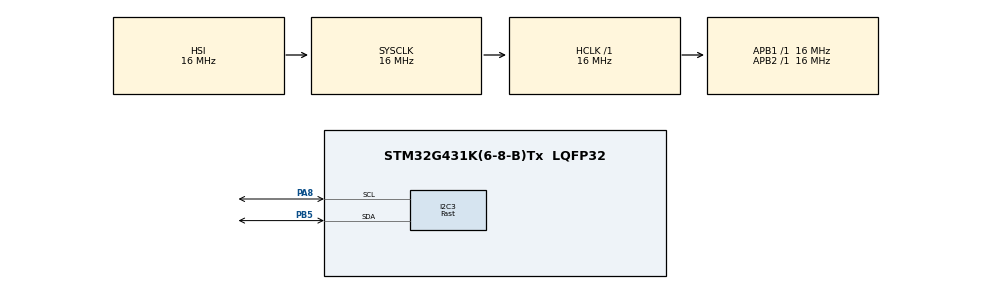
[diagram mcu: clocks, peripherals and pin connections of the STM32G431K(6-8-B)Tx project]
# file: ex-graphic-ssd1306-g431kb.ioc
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I2C3.I2C_Speed_Mode=I2C_Fast
I2C3.Timing=0x00300617
Mcu.Family=STM32G4
Mcu.Name=STM32G431K(6-8-B)Tx
Mcu.Package=LQFP32
NVIC.PriorityGroup=NVIC_PRIORITYGROUP_4
PA13.Mode=Serial_Wire
PA13.Signal=SYS_JTMS-SWDIO
PA14.Mode=Serial_Wire
PA14.Signal=SYS_JTCK-SWCLK
PA8.Mode=I2C
PA8.Signal=I2C3_SCL
PB5.Mode=I2C
PB5.Signal=I2C3_SDA
ProjectManager.HeapSize=0x200
ProjectManager.StackSize=0x400
ProjectManager.TargetToolchain=STM32CubeIDE
RCC.AHBFreq_Value=16000000
RCC.APB1Freq_Value=16000000
RCC.APB1TimFreq_Value=16000000
RCC.APB2Freq_Value=16000000
RCC.APB2TimFreq_Value=16000000
RCC.CortexFreq_Value=16000000
RCC.EXTERNAL_CLOCK_VALUE=12288000
RCC.HCLKFreq_Value=16000000
RCC.HSE_VALUE=8000000
RCC.HSI48_VALUE=48000000
RCC.HSI_VALUE=16000000
RCC.LSE_VALUE=32768
RCC.SYSCLKFreq_VALUE=16000000
RCC.USBFreq_Value=64000000
RCC.VCOOutputFreq_Value=128000000
VP_SYS_VS_DBSignals.Mode=DisableDeadBatterySignals
board=custom

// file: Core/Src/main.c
/* USER CODE BEGIN Header */
/**
  ******************************************************************************
  * @file           : main.c
  * @brief          : Main program body
  ******************************************************************************
  * @attention
  *
  * Copyright (c) 2024 STMicroelectronics.
  * All rights reserved.
  *
  * This software is licensed under terms that can be found in the LICENSE file
  * in the root directory of this software component.
  * If no LICENSE file comes with this software, it is provided AS-IS.
  *
  ******************************************************************************
  */
/* USER CODE END Header */
#include "main.h"

/* USER CODE BEGIN Includes */
#include "drivers/ssd1306/ssd1306.h"

#include "GraphicDisplay.h"
#include "GraphicDisplay_Fonts.h"
/* USER CODE END Includes */

I2C_HandleTypeDef hi2c3;

/* USER CODE BEGIN PV */
#define cobra_width 	 64
#define cobra_height 	 64
const unsigned char cobra_bmp [] ={
0x00,0x00,0x00,0xb4,0x00,0x00,0x00,0x00,0x00,0x00,0x00,0xef,0x03,0x00,0x00,0x00,
0x00,0x00,0xc0,0x00,0x06,0x00,0x00,0x00,0x00,0x00,0x60,0x00,0x18,0x00,0x00,0x00,
0x00,0x00,0x30,0x0e,0x30,0x00,0x00,0x00,0x00,0x00,0x98,0x1b,0x70,0x00,0x00,0x00,
0x00,0x00,0x88,0x30,0xd0,0x00,0x00,0x00,0x00,0x00,0x84,0x68,0x90,0x01,0x00,0x00,
0x00,0x00,0xc6,0xdc,0x30,0x03,0x00,0x00,0x00,0x00,0x82,0x87,0x21,0x06,0x00,0x00,
0x00,0x00,0x02,0x03,0xc3,0x0c,0x00,0x00,0x00,0x00,0x03,0x01,0x86,0x3f,0x00,0x00,
0x00,0x00,0x81,0x01,0x0c,0xe0,0x00,0x00,0x00,0x00,0x81,0x00,0x18,0x80,0x03,0x00,
0x00,0x00,0x83,0x00,0x70,0x00,0x06,0x00,0x00,0x00,0x8f,0x00,0x40,0x00,0x04,0x00,
0x00,0x00,0x99,0x00,0xc0,0x01,0x0c,0x00,0x00,0x00,0x91,0x00,0x00,0x03,0x04,0x00,
0x00,0x00,0xb1,0x01,0x00,0x06,0x04,0x00,0x00,0x00,0x93,0x00,0x00,0x0c,0x0c,0x00,
0x00,0x00,0x11,0x01,0x00,0x08,0x04,0x00,0x00,0x00,0x1a,0x03,0x00,0x18,0x08,0x00,
0x00,0x00,0x0e,0x06,0x00,0x10,0x08,0x00,0x00,0x00,0x06,0x06,0x00,0x30,0x08,0x00,
0x00,0x00,0x04,0x1b,0x00,0x60,0x0c,0x00,0x00,0x00,0x0c,0x32,0x00,0xc0,0x07,0x00,
0x00,0x00,0x18,0x63,0x00,0x80,0x04,0x00,0x00,0x00,0x30,0xc6,0x00,0x00,0x0c,0x00,
0x00,0x00,0x60,0xcc,0x01,0x00,0x08,0x00,0x00,0x00,0xc0,0x78,0x03,0x00,0x38,0x00,
0x00,0x00,0x80,0x01,0x06,0x00,0x68,0x00,0x00,0x00,0x00,0x03,0x1c,0x00,0x0c,0x00,
0x00,0x00,0x20,0x06,0x18,0x00,0x00,0x00,0x00,0x00,0xfe,0xff,0xff,0x7f,0x00,0x00,
0x00,0x00,0x03,0x20,0x08,0xc0,0x00,0x00,0x00,0x00,0x01,0x60,0x0c,0x80,0x00,0x00,
0x00,0x80,0x01,0xc0,0x07,0x80,0x01,0x00,0x00,0x80,0x00,0x80,0x02,0x00,0x01,0x00,
0x00,0x00,0x01,0x00,0x00,0x80,0x00,0x00,0x00,0x00,0x03,0x00,0x00,0xc0,0x00,0x00,
0x00,0xe0,0xff,0xff,0xff,0xff,0x07,0x00,0x00,0x38,0x49,0xb2,0x2c,0x49,0x1a,0x00,
0x00,0x08,0x00,0x60,0x08,0x00,0x10,0x00,0x00,0x0c,0x00,0x40,0x0e,0x00,0x30,0x00,
0x00,0x04,0xf0,0xc0,0x03,0x1e,0x20,0x00,0x00,0x08,0x98,0x01,0x00,0x33,0x30,0x00,
0x00,0x08,0x0c,0x01,0x00,0x61,0x10,0x00,0x00,0xba,0x4c,0x2b,0xd5,0x65,0x5e,0x00,
0x80,0xff,0xff,0xff,0xff,0xff,0xff,0x01,0xc0,0x00,0x00,0x20,0x08,0x00,0x00,0x03,
0x40,0x00,0x00,0x60,0x0c,0x00,0x00,0x02,0x60,0x00,0x14,0xc0,0x07,0x50,0x00,0x06,
0x20,0x00,0x3e,0x00,0x01,0xf8,0x00,0x04,0x40,0x00,0x63,0x00,0x00,0x8c,0x01,0x02,
0xc0,0x00,0x41,0x00,0x00,0x04,0x01,0x03,0xf8,0xff,0xff,0xff,0xff,0xff,0xff,0x1f,
0x0e,0x82,0x20,0x28,0x89,0x20,0x08,0x72,0x02,0x00,0x00,0x60,0x0c,0x00,0x00,0x40,
0x03,0x40,0x00,0x40,0x06,0x00,0x02,0xc0,0x02,0xf0,0x01,0xc0,0x03,0x80,0x0f,0x80,
0x03,0x18,0x03,0x00,0x00,0xc0,0x18,0x40,0x02,0x08,0x02,0x00,0x00,0x40,0x10,0x60,
0xae,0x5a,0x57,0x55,0xb5,0xea,0x5e,0x35,0xf8,0xff,0xff,0xff,0xff,0xff,0xff,0x1f};
/* USER CODE END PV */

void SystemClock_Config(void);
static void MX_GPIO_Init(void);
static void MX_I2C3_Init(void);

/* USER CODE BEGIN 0 */
uint8_t _ssd_i2c_write(uint8_t i2cAddr, uint8_t reg, uint8_t *buff, uint32_t len){
	return (uint8_t)HAL_I2C_Mem_Write(&hi2c3, (i2cAddr << 1), reg, 1, buff, len, 100);
}
/* USER CODE END 0 */

int main(void)
{

  /* USER CODE BEGIN 1 */
	ssd1306_t Ssd1306 = {0};
	ssd1306_params_t Ssd1306_params = {
			.Mode = SSD1306_MODE_I2C,
			.u32Heigth = 64,
			.u32Width = 128,
			.bUseExternalFrameBuffer = false,
			.delayMs = HAL_Delay,
			.i2cWrite = _ssd_i2c_write,
			.u8I2CAddr = 0x3C
	};

	gd_t Graphic = {0};
	gd_params_t Graphic_params = {
			.DisplayDriver = Gd_Driver_SSD1306,
			.DisplayHandle = (void*)&Ssd1306,
			.u32Height = 64,
			.u32Width = 128
	};
  /* USER CODE END 1 */

  /* MCU Configuration--------------------------------------------------------*/

  /* Reset of all peripherals, Initializes the Flash interface and the Systick. */
  HAL_Init();

  /* Configure the system clock */
  SystemClock_Config();

  /* Initialize all configured peripherals */
  MX_GPIO_Init();
  MX_I2C3_Init();
  /* USER CODE BEGIN 2 */
  SSD1306_Init(&Ssd1306, &Ssd1306_params);

  GD_Init(&Graphic, &Graphic_params);
  GD_Fill(&Graphic, GD_BLACK);

  GD_DrawBitmap(&Graphic, 0, 0, cobra_bmp, cobra_width, cobra_height, GD_WHITE);

  GD_SetCursor(&Graphic, 66, 10);
  GD_WriteString(&Graphic, "SSD1306", Font_7x10, GD_WHITE);

  GD_DrawCircle(&Graphic, 90, 30, 7, GD_WHITE);
  GD_FillCircle(&Graphic, 90, 30, 5, GD_WHITE);

  GD_DrawRectangle(&Graphic, 78, 43, 122, 62, GD_WHITE);
  GD_FillRectangle(&Graphic, 80, 45, 120, 60, GD_WHITE);

  GD_UpdateScreen(&Graphic);
  /* USER CODE END 2 */

  /* Infinite loop */
  while (1)
  {

  }
}

void SystemClock_Config(void)
{
  RCC_OscInitTypeDef RCC_OscInitStruct = {0};
  RCC_ClkInitTypeDef RCC_ClkInitStruct = {0};

  /** Configure the main internal regulator output voltage
  */
  HAL_PWREx_ControlVoltageScaling(PWR_REGULATOR_VOLTAGE_SCALE1);

  /** Initializes the RCC Oscillators according to the specified parameters
  * in the RCC_OscInitTypeDef structure.
  */
  RCC_OscInitStruct.OscillatorType = RCC_OSCILLATORTYPE_HSI;
  RCC_OscInitStruct.HSIState = RCC_HSI_ON;
  RCC_OscInitStruct.HSICalibrationValue = RCC_HSICALIBRATION_DEFAULT;
  RCC_OscInitStruct.PLL.PLLState = RCC_PLL_NONE;
  if (HAL_RCC_OscConfig(&RCC_OscInitStruct) != HAL_OK)
  {
    Error_Handler();
  }

  /** Initializes the CPU, AHB and APB buses clocks
  */
  RCC_ClkInitStruct.ClockType = RCC_CLOCKTYPE_HCLK|RCC_CLOCKTYPE_SYSCLK
                              |RCC_CLOCKTYPE_PCLK1|RCC_CLOCKTYPE_PCLK2;
  RCC_ClkInitStruct.SYSCLKSource = RCC_SYSCLKSOURCE_HSI;
  RCC_ClkInitStruct.AHBCLKDivider = RCC_SYSCLK_DIV1;
  RCC_ClkInitStruct.APB1CLKDivider = RCC_HCLK_DIV1;
  RCC_ClkInitStruct.APB2CLKDivider = RCC_HCLK_DIV1;

  if (HAL_RCC_ClockConfig(&RCC_ClkInitStruct, FLASH_LATENCY_0) != HAL_OK)
  {
    Error_Handler();
  }
}

static void MX_I2C3_Init(void)
{

  hi2c3.Instance = I2C3;
  hi2c3.Init.Timing = 0x00300617;
  hi2c3.Init.OwnAddress1 = 0;
  hi2c3.Init.AddressingMode = I2C_ADDRESSINGMODE_7BIT;
  hi2c3.Init.DualAddressMode = I2C_DUALADDRESS_DISABLE;
  hi2c3.Init.OwnAddress2 = 0;
  hi2c3.Init.OwnAddress2Masks = I2C_OA2_NOMASK;
  hi2c3.Init.GeneralCallMode = I2C_GENERALCALL_DISABLE;
  hi2c3.Init.NoStretchMode = I2C_NOSTRETCH_DISABLE;
  if (HAL_I2C_Init(&hi2c3) != HAL_OK)
  {
    Error_Handler();
  }

  /** Configure Analogue filter
  */
  if (HAL_I2CEx_ConfigAnalogFilter(&hi2c3, I2C_ANALOGFILTER_ENABLE) != HAL_OK)
  {
    Error_Handler();
  }

  /** Configure Digital filter
  */
  if (HAL_I2CEx_ConfigDigitalFilter(&hi2c3, 0) != HAL_OK)
  {
    Error_Handler();
  }

}

static void MX_GPIO_Init(void)
{

  /* GPIO Ports Clock Enable */
  __HAL_RCC_GPIOA_CLK_ENABLE();
  __HAL_RCC_GPIOB_CLK_ENABLE();

}

void Error_Handler(void)
{
  __disable_irq();
  while (1)
  {
  }
}
